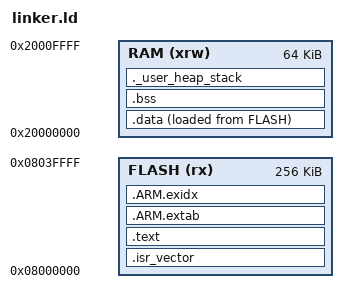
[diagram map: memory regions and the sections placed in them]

/* STM32F401CCU6: 256 KB Flash, 64 KB SRAM */

ENTRY(Reset_Handler)

_estack = ORIGIN(RAM) + LENGTH(RAM);

_Min_Heap_Size  = 0x200;
_Min_Stack_Size = 0x400;

MEMORY
{
    FLASH (rx)  : ORIGIN = 0x08000000, LENGTH = 256K
    RAM   (xrw) : ORIGIN = 0x20000000, LENGTH = 64K
}

SECTIONS
{
    /* Interrupt vector table must start in Flash */
    .isr_vector :
    {
        . = ALIGN(4);
        KEEP(*(.isr_vector))
        . = ALIGN(4);
    } > FLASH

    /* Program code and constants */
    .text :
    {
        . = ALIGN(4);
        *(.text)
        *(.text*)
        *(.rodata)
        *(.rodata*)
        *(.glue_7)
        *(.glue_7t)
        KEEP(*(.init))
        KEEP(*(.fini))
        . = ALIGN(4);
        _etext = .;
    } > FLASH

    /* Exception index tables */
    .ARM.extab :
    {
        *(.ARM.extab*)
    } > FLASH

    .ARM.exidx :
    {
        __exidx_start = .;
        *(.ARM.exidx*)
        __exidx_end = .;
    } > FLASH

    /* Initial values for .data are stored in Flash */
    _sidata = LOADADDR(.data);

    .data :
    {
        . = ALIGN(4);
        _sdata = .;
        *(.data)
        *(.data*)
        . = ALIGN(4);
        _edata = .;
    } > RAM AT> FLASH

    /* Zero-initialized global and static variables */
    .bss :
    {
        . = ALIGN(4);
        _sbss = .;
        __bss_start__ = _sbss;
        *(.bss)
        *(.bss*)
        *(COMMON)
        . = ALIGN(4);
        _ebss = .;
        __bss_end__ = .;
    } > RAM

    /* Reserve a small heap and stack area */
    ._user_heap_stack :
    {
        . = ALIGN(8);
        PROVIDE(end = .);
        PROVIDE(_end = .);
        . = . + _Min_Heap_Size;
        . = . + _Min_Stack_Size;
        . = ALIGN(8);
    } > RAM

    /* ARM toolchain metadata */
    .ARM.attributes 0 :
    {
        *(.ARM.attributes)
    }

    /DISCARD/ :
    {
        *(.note.GNU-stack)
    }
}

